# STM32L083xx register map
File version: 1.0
Registers are 32-bit, read-write, reset 0x0 unless marked. A register's access mark holds for its fields unless they carry their own. Offsets are from the block's base; lines under a group give offsets from that group; [hi:lo] are bit positions; {n}, {i} and the like mark numbered series; 'fields as' and 'values as' point back to an identical list; <NAME> marks a mode.

## Memory map
0x1FF80000 OB — Option Bytes Registers
0x40000000 TIM2 — TIM
0x40000400 TIM3 — TIM
0x40001000 TIM6 — TIM
0x40001400 TIM7 — TIM
0x40002400 LCD
0x40002800 RTC — Real-Time Clock
0x40002C00 WWDG — Window WATCHDOG
0x40003000 IWDG — Independent WATCHDOG
0x40003800 SPI2 — Serial Peripheral Interface
0x40004400 USART2 — Universal Synchronous Asynchronous Receiver Transmitter
0x40004800 LPUART1 — Universal Synchronous Asynchronous Receiver Transmitter
0x40004C00 USART4 — Universal Synchronous Asynchronous Receiver Transmitter
0x40005000 USART5 — Universal Synchronous Asynchronous Receiver Transmitter
0x40005400 I2C1 — Inter-integrated Circuit Interface
0x40005800 I2C2 — Inter-integrated Circuit Interface
0x40005C00 USB — Universal Serial Bus Full Speed Device
0x40006C00 CRS — Clock Recovery System
0x40007000 PWR — Power Control
0x40007400 DAC — Digital to Analog Converter
0x40007400 DAC1 — Digital to Analog Converter
0x40007800 I2C3 — Inter-integrated Circuit Interface
0x40007C00 LPTIM1 — LPTIMIMER
0x40010000 SYSCFG — SysTem Configuration
0x40010018 COMP1 — Comparator
0x40010018 COMP12_COMMON
0x4001001C COMP2 — Comparator
0x40010400 EXTI — External Interrupt/Event Controller
0x40010800 TIM21 — TIM
0x40011400 TIM22 — TIM
0x40011C00 FIREWALL — MIFARE Firewall
0x40012400 ADC1 — Analog to Digital Converter
0x40013000 SPI1 — Serial Peripheral Interface
0x40013800 USART1 — Universal Synchronous Asynchronous Receiver Transmitter
0x40015800 DBGMCU — Debug MCU
0x40020000 DMA1
0x40021000 RCC — Reset and Clock Control
0x40022000 FLASH — FLASH Registers
0x40023000 CRC — CRC calculation unit
0x40024000 TSC — Touch Sensing Controller (TSC)
0x40025000 RNG — Random numbers generator
0x40026000 AES — AES hardware accelerator
0x50000000 GPIOA — General Purpose IO
0x50000400 GPIOB — General Purpose IO
0x50000800 GPIOC — General Purpose IO
0x50000C00 GPIOD — General Purpose IO
0x50001000 GPIOE — General Purpose IO
0x50001C00 GPIOH — General Purpose IO

## Interrupts
0 WWDG — Window WatchDog Interrupt
2 RTC — RTC through EXTI Line Interrupt
3 FLASH — FLASH Interrupt
4 RCC_CRS (CRS, RCC) — RCC and CRS Interrupts
5 EXTI0_1 (EXTI) — EXTI Line 0 and 1 Interrupts
6 EXTI2_3 (EXTI) — EXTI Line 2 and 3 Interrupts
7 EXTI4_15 (EXTI) — EXTI Line 4 to 15 Interrupts
8 TSC — TSC Interrupt
9 DMA1_Channel1 (DMA1) — DMA1 Channel 1 Interrupt
10 DMA1_Channel2_3 (DMA1) — DMA1 Channel 2 and Channel 3 Interrupts
11 DMA1_Channel4_5_6_7 (DMA1) — DMA1 Channel 4, Channel 5, Channel 6 and Channel 7 Interrupts
12 ADC1_COMP (ADC1) — ADC1, COMP1 and COMP2 Interrupts
13 LPTIM1 — LPTIM1 Interrupt
14 USART4_5 (USART4) — USART4 and USART5 Interrupt
15 TIM2 — TIM2 Interrupt
16 TIM3 — TIM3 Interrupt
17 TIM6_DAC (TIM6, DAC) — TIM6 and DAC Interrupts
18 TIM7 — TIM7 Interrupt
20 TIM21 — TIM21 Interrupt
21 I2C3 — I2C3 Interrupt
22 TIM22 — TIM22 Interrupt
23 I2C1 — I2C1 Interrupt
24 I2C2 — I2C2 Interrupt
25 SPI1 — SPI1 Interrupt
26 SPI2 — SPI2 Interrupt
27 USART1 — USART1 Interrupt
28 USART2 — USART2 Interrupt
29 AES_RNG_LPUART1 (LPUART1, RNG, AES) — AES and RNG and LPUART1 Interrupts
30 LCD — LCD Interrupt
31 USB — USB global Interrupt

## OB — Option Bytes Registers
Base 0x1FF80000
0x00 RDP — Read protection register
0x04 USER
0x08 WRP01 — write protection Bytes 0 and 1
0x0C WRP23 — write protection Bytes 2 and 3
0x10 WRP45 — write protection Bytes 4 and 5

## TIM6 — TIM
Base 0x40001000
Same registers: TIM7 0x40001400
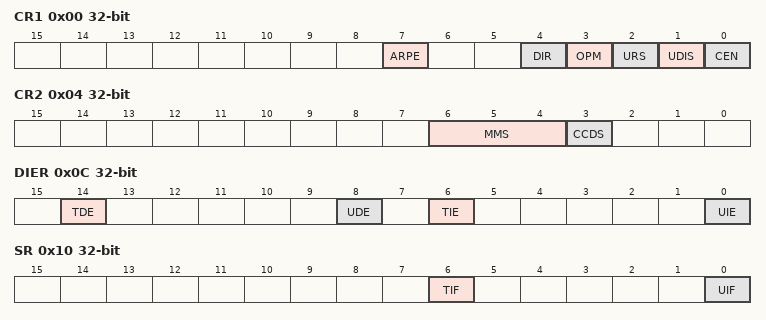
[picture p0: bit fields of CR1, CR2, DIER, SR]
0x00 CR1 — TIM control register 1
  [7] ARPE — Auto-reload preload enable
  [4] DIR — Direction
    0=UP (Timer counter counts up); 1=DOWN (Timer counter counts down)
  [3] OPM — One pulse mode
    1=SINGLE (Counter stops counting at the next update event); 0=REPETITIVE (Counter is not stopped at update event)
  [2] URS — Update request source
    0=REGULAR (Counter overflow/underflow, Setting the UG bit or Update generation through the slave mode controller generates an update request); 1=COUNTER (Only counter overflow/underflow generates an update request)
  [1] UDIS — Update disable
  [0] CEN — Counter enable
0x04 CR2 — TIM control register 2
  [6:4] MMS — MMS[2:0] bits (Master Mode Selection)
    0=RESET (UG bit from the TIMx_EGR register is used as trigger output); 1=ENABLE (Counter Enable signal (CNT_EN) is used as trigger output); 2=UPDATE (Update event is used as trigger output); 3=CC1IF (CC1 capture or a compare match is used as trigger output); {v}=OC{v-3}REF (OC{v-3}REF signal is used as trigger output) (v=4..7)
  [3] CCDS — Capture/Compare DMA Selection
    0=CC (CCx DMA request sent when CCx event occurs); 1=UPDATE (CCx DMA requests sent when update event occurs)
0x0C DIER — TIM DMA/interrupt enable register
  [14] TDE — Trigger DMA request enable
  [8] UDE — Update DMA request enable
  [6] TIE — Trigger interrupt enable
  [0] UIE — Update interrupt enable
0x10 SR — TIM status register
  [6] TIF — Trigger interrupt Flag
  [0] UIF — Update interrupt Flag
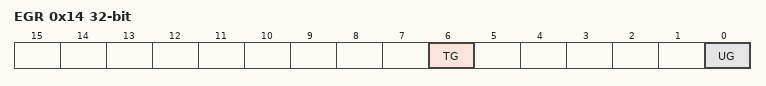
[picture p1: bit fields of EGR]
0x14 EGR — TIM event generation register
  [6] TG — Trigger Generation
  [0] UG — Update Generation
0x24 CNT — TIM counter register
  [15:0] CNT — Counter Value
0x28 PSC — TIM prescaler register
  [15:0] PSC — Prescaler Value
0x2C ARR — TIM auto-reload register
  [15:0] ARR — actual auto-reload Value
0x4C DMAR — TIM DMA address for full transfer register
  [15:0] DMAB — DMA register for burst accesses
0x50 OR — TIM option register
